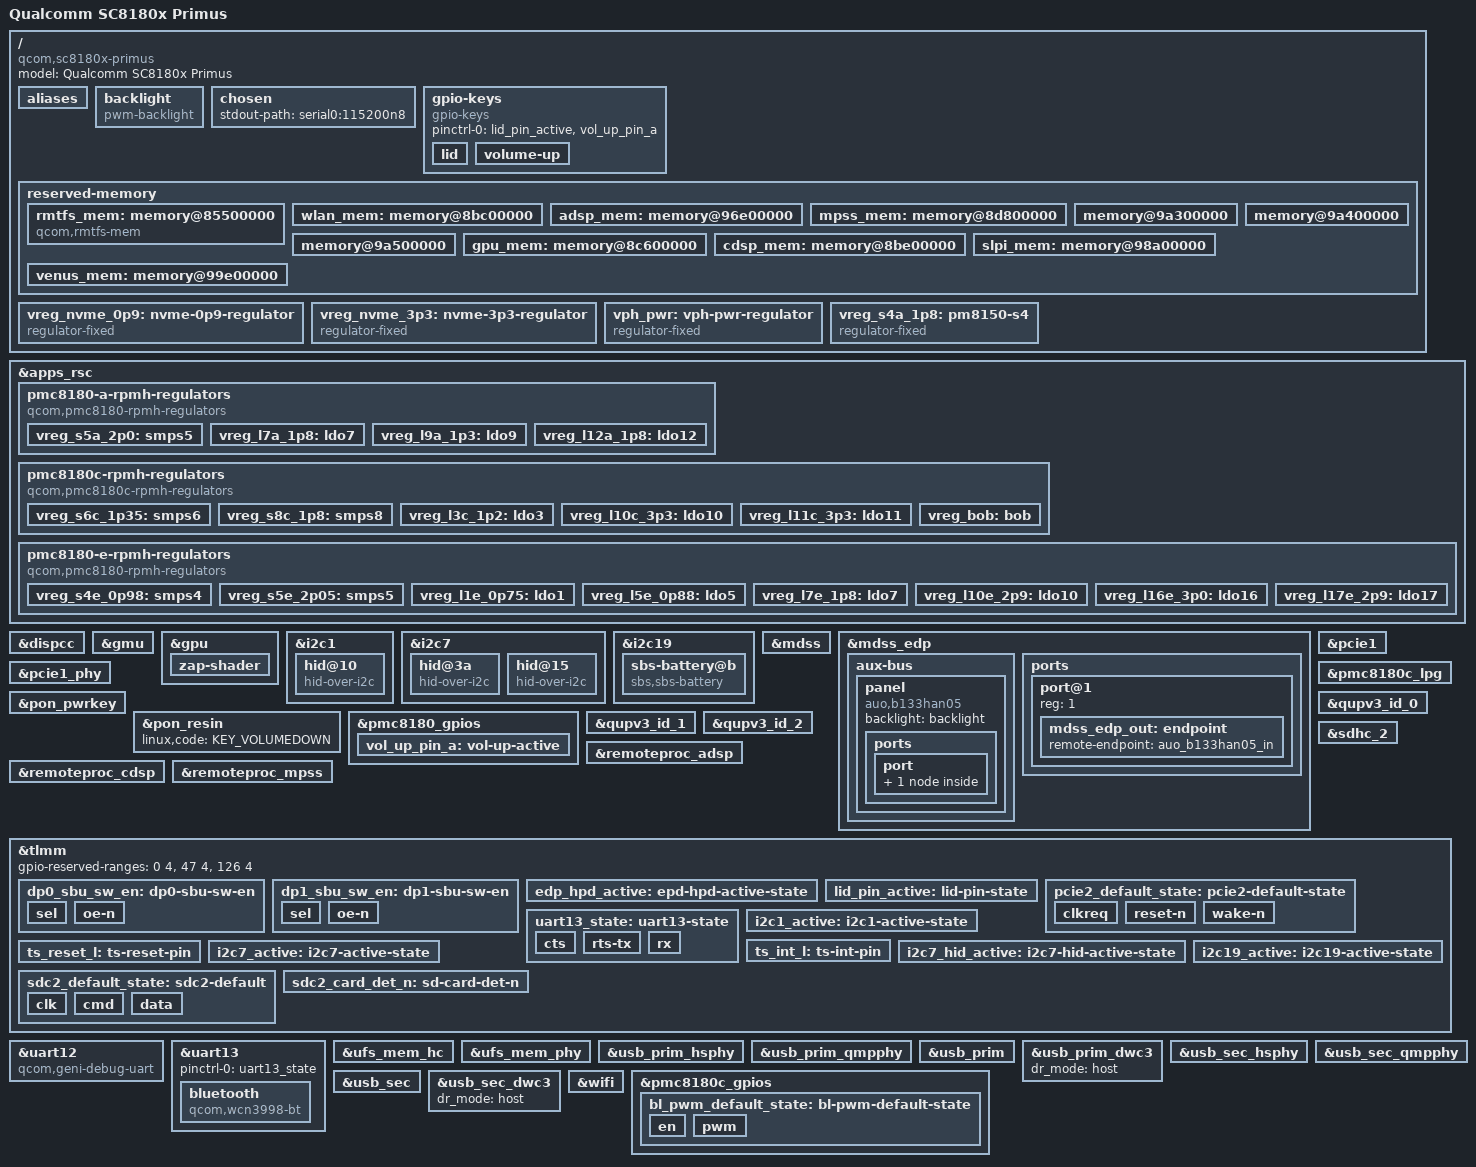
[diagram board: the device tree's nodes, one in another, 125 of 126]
// SPDX-License-Identifier: BSD-3-Clause
/*
 * Copyright (c) 2017-2019, The Linux Foundation. All rights reserved.
 * Copyright (c) 2020-2021, Linaro Limited
 */

/dts-v1/;

#include <dt-bindings/gpio/gpio.h>
#include <dt-bindings/input/gpio-keys.h>
#include <dt-bindings/input/input.h>
#include <dt-bindings/regulator/qcom,rpmh-regulator.h>
#include "sc8180x.dtsi"
#include "pmc8180.dtsi"
#include "pmc8180c.dtsi"

/ {
	model = "Qualcomm SC8180x Primus";
	compatible = "qcom,sc8180x-primus", "qcom,sc8180x";

	aliases {
		serial0 = &uart12;
		serial1 = &uart13;
		mmc0 = &sdhc_2;
	};

	backlight: backlight {
		compatible = "pwm-backlight";
		pwms = <&pmc8180c_lpg 4 1000000>;
		enable-gpios = <&pmc8180c_gpios 8 GPIO_ACTIVE_HIGH>;

		pinctrl-names = "default";
		pinctrl-0 = <&bl_pwm_default_state>;
	};

	chosen {
		stdout-path = "serial0:115200n8";
	};

	gpio-keys {
		compatible = "gpio-keys";

		pinctrl-names = "default";
		pinctrl-0 = <&lid_pin_active>, <&vol_up_pin_a>;

		lid {
			gpios = <&tlmm 121 GPIO_ACTIVE_HIGH>;
			linux,input-type = <EV_SW>;
			linux,code = <SW_LID>;
			wakeup-source;
			wakeup-event-action = <EV_ACT_DEASSERTED>;
		};

		volume-up {
			label = "volume_up";
			gpios = <&pmc8180_gpios 6 GPIO_ACTIVE_LOW>;
			linux,input-type = <1>;
			linux,code = <KEY_VOLUMEUP>;
			gpio-key,wakeup;
			debounce-interval = <15>;
			linux,can-disable;
		};
	};

	reserved-memory {
		rmtfs_mem: memory@85500000 {
			compatible = "qcom,rmtfs-mem";
			reg = <0x0 0x85500000 0x0 0x200000>;
			no-map;

			qcom,client-id = <1>;
			qcom,vmid = <15>;
		};

		wlan_mem: memory@8bc00000 {
			reg = <0x0 0x8bc00000 0x0 0x180000>;
			no-map;
		};

		adsp_mem: memory@96e00000 {
			reg = <0x0 0x96e00000 0x0 0x1c00000>;
			no-map;
		};

		mpss_mem: memory@8d800000 {
			reg = <0x0 0x8d800000 0x0 0x9600000>;
			no-map;
		};

		memory@9a300000 {
			reg = <0x0 0x9a500000 0x0 0x100000>;
			no-map;
		};

		memory@9a400000 {
			reg = <0x0 0x9a400000 0x0 0x100000>;
			no-map;
		};

		memory@9a500000 {
			reg = <0x0 0x9a500000 0x0 0x600000>;
			no-map;
		};

		gpu_mem: memory@8c600000 {
			reg = <0x0 0x8c600000 0x0 0x5000>;
			no-map;
		};

		cdsp_mem: memory@8be00000 {
			reg = <0x0 0x8be00000 0x0 0x800000>;
			no-map;
		};

		slpi_mem: memory@98a00000 {
			reg = <0x0 0x98a00000 0x0 0x1400000>;
			no-map;
		};

		venus_mem: memory@99e00000 {
			reg = <0x0 0x99e00000 0x0 0x500000>;
			no-map;
		};
	};

	vreg_nvme_0p9: nvme-0p9-regulator {
		compatible = "regulator-fixed";
		regulator-name = "vreg_nvme_0p9";

		regulator-min-microvolt = <900000>;
		regulator-max-microvolt = <900000>;

		regulator-always-on;
	};

	vreg_nvme_3p3: nvme-3p3-regulator {
		compatible = "regulator-fixed";
		regulator-name = "vreg_nvme_3p3";

		regulator-min-microvolt = <3300000>;
		regulator-max-microvolt = <3300000>;

		gpio = <&pmc8180c_gpios 11 0>;
		enable-active-high;

		regulator-always-on;
	};

	vph_pwr: vph-pwr-regulator {
		compatible = "regulator-fixed";
		regulator-name = "vph_pwr";
		regulator-min-microvolt = <3700000>;
		regulator-max-microvolt = <3700000>;
	};

	vreg_s4a_1p8: pm8150-s4 {
		compatible = "regulator-fixed";
		regulator-name = "vreg_s4a_1p8";

		regulator-min-microvolt = <1800000>;
		regulator-max-microvolt = <1800000>;

		regulator-always-on;
		regulator-boot-on;

		vin-supply = <&vph_pwr>;
	};
};

&apps_rsc {
	pmc8180-a-rpmh-regulators {
		compatible = "qcom,pmc8180-rpmh-regulators";
		qcom,pmic-id = "a";

		vdd-s5-supply = <&vph_pwr>;
		vdd-l7-l12-l14-l15-supply = <&vreg_s5a_2p0>;

		vreg_s5a_2p0: smps5 {
			regulator-min-microvolt = <2040000>;
			regulator-max-microvolt = <2100000>;
		};

		// vreg_l6a_1p2: ldo6 {
		// 	regulator-min-microvolt = <1200000>;
		// 	regulator-max-microvolt = <1200000>;
		// 	regulator-initial-mode = <RPMH_REGULATOR_MODE_HPM>;
		// };

		vreg_l7a_1p8: ldo7 {
			regulator-min-microvolt = <1800000>;
			regulator-max-microvolt = <1800000>;
			regulator-initial-mode = <RPMH_REGULATOR_MODE_HPM>;
		};


		vreg_l9a_1p3: ldo9 {
			regulator-min-microvolt = <1296000>;
			regulator-max-microvolt = <1304000>;
			regulator-initial-mode = <RPMH_REGULATOR_MODE_HPM>;
		};

		vreg_l12a_1p8: ldo12 {
			regulator-min-microvolt = <1800000>;
			regulator-max-microvolt = <1800000>;
			regulator-initial-mode = <RPMH_REGULATOR_MODE_HPM>;
		};
	};

	pmc8180c-rpmh-regulators {
		compatible = "qcom,pmc8180c-rpmh-regulators";
		qcom,pmic-id = "c";

		vdd-s6-supply = <&vph_pwr>;
		vdd-s8-supply = <&vph_pwr>;
		vdd-l2-l3-supply = <&vreg_s6c_1p35>;
		vdd-bob-supply = <&vph_pwr>;

		vreg_s6c_1p35: smps6 {
			regulator-min-microvolt = <1350000>;
			regulator-max-microvolt = <1372000>;
			regulator-initial-mode = <RPMH_REGULATOR_MODE_HPM>;
		};

		vreg_s8c_1p8: smps8 {
			regulator-min-microvolt = <1800000>;
			regulator-max-microvolt = <1800000>;
			regulator-initial-mode = <RPMH_REGULATOR_MODE_HPM>;
			regulator-always-on;
		};

		// vreg_l2c_1p2: ldo2 {
		// 	regulator-min-microvolt = <1200000>;
		// 	regulator-max-microvolt = <1200000>;
		// 	regulator-initial-mode = <RPMH_REGULATOR_MODE_HPM>;
		// };

		vreg_l3c_1p2: ldo3 {
			regulator-min-microvolt = <1200000>;
			regulator-max-microvolt = <1200000>;
			regulator-initial-mode = <RPMH_REGULATOR_MODE_HPM>;
		};

		// vreg_l6c: ldo6 {
		// 	regulator-min-microvolt = <1800000>;
		// 	regulator-max-microvolt = <2950000>;
		// 	regulator-initial-mode = <RPMH_REGULATOR_MODE_HPM>;
		// };

		// vreg_l9c_2p9: ldo9 {
		// 	regulator-min-microvolt = <2504000>;
		// 	regulator-max-microvolt = <2904000>;
		// 	regulator-initial-mode = <RPMH_REGULATOR_MODE_HPM>;
		// };

		vreg_l10c_3p3: ldo10 {
			regulator-min-microvolt = <3000000>;
			regulator-max-microvolt = <3312000>;
			regulator-initial-mode = <RPMH_REGULATOR_MODE_HPM>;
		};

		vreg_l11c_3p3: ldo11 {
			regulator-min-microvolt = <3296000>;
			regulator-max-microvolt = <3304000>;
			regulator-initial-mode = <RPMH_REGULATOR_MODE_HPM>;
		};

		vreg_bob: bob {
			regulator-min-microvolt = <3296000>;
			regulator-max-microvolt = <3350000>;
			regulator-initial-mode = <RPMH_REGULATOR_MODE_HPM>;
		};
	};

	pmc8180-e-rpmh-regulators {
		compatible = "qcom,pmc8180-rpmh-regulators";
		qcom,pmic-id = "e";

		vdd-s4-supply = <&vph_pwr>;
		vdd-s5-supply = <&vph_pwr>;
		vdd-l2-l10-supply = <&vreg_bob>;
		vdd-l3-l4-l5-l18-supply = <&vreg_s4e_0p98>;
		vdd-l7-l12-l14-l15-supply = <&vreg_s5e_2p05>;
		vdd-l13-l16-l17-supply = <&vreg_bob>;

		vreg_s4e_0p98: smps4 {
			regulator-min-microvolt = <992000>;
			regulator-max-microvolt = <992000>;
			regulator-initial-mode = <RPMH_REGULATOR_MODE_HPM>;
		};

		vreg_s5e_2p05: smps5 {
			regulator-min-microvolt = <2040000>;
			regulator-max-microvolt = <2040000>;
			regulator-initial-mode = <RPMH_REGULATOR_MODE_HPM>;
		};

		vreg_l1e_0p75: ldo1 {
			regulator-min-microvolt = <752000>;
			regulator-max-microvolt = <752000>;
			regulator-initial-mode = <RPMH_REGULATOR_MODE_HPM>;
		};

		vreg_l5e_0p88: ldo5 {
			regulator-min-microvolt = <880000>;
			regulator-max-microvolt = <880000>;
			regulator-initial-mode = <RPMH_REGULATOR_MODE_HPM>;
		};

		vreg_l7e_1p8: ldo7 {
			regulator-min-microvolt = <1800000>;
			regulator-max-microvolt = <1800000>;
			regulator-initial-mode = <RPMH_REGULATOR_MODE_HPM>;
		};

		// vreg_l9e_0p88: ldo9 {
		// 	regulator-min-microvolt = <880000>;
		// 	regulator-max-microvolt = <880000>;
		// 	regulator-initial-mode = <RPMH_REGULATOR_MODE_HPM>;
		// };

		vreg_l10e_2p9: ldo10 {
			regulator-min-microvolt = <2904000>;
			regulator-max-microvolt = <2904000>;
			regulator-initial-mode = <RPMH_REGULATOR_MODE_HPM>;
		};

		// vreg_l12e_1p8: ldo12 {
		// 	regulator-min-microvolt = <1800000>;
		// 	regulator-max-microvolt = <1800000>;
		// 	regulator-initial-mode = <RPMH_REGULATOR_MODE_HPM>;
		// };

		// vreg_l14e_1p8: ldo14 {
		// 	regulator-min-microvolt = <1800000>;
		// 	regulator-max-microvolt = <1800000>;
		// 	regulator-initial-mode = <RPMH_REGULATOR_MODE_HPM>;
		// };

		// vreg_l15e_1p8: ldo15 {
		// 	regulator-min-microvolt = <1800000>;
		// 	regulator-max-microvolt = <1800000>;
		// 	regulator-initial-mode = <RPMH_REGULATOR_MODE_HPM>;
		// };

		vreg_l16e_3p0: ldo16 {
			regulator-min-microvolt = <3072000>;
			regulator-max-microvolt = <3072000>;
			regulator-initial-mode = <RPMH_REGULATOR_MODE_HPM>;
		};

		vreg_l17e_2p9: ldo17 {
			regulator-min-microvolt = <2960000>;
			regulator-max-microvolt = <2960000>;
			regulator-initial-mode = <RPMH_REGULATOR_MODE_HPM>;
		};
	};
};

&dispcc {
	status = "okay";
};

&gmu {
	status = "okay";
};

&gpu {
	status = "okay";

	zap-shader {
		memory-region = <&gpu_mem>;
		firmware-name = "qcom/sc8180x/qcdxkmsuc8180.mbn";
	};
};

&i2c1 {
	status = "okay";
	clock-frequency = <100000>;

	pinctrl-names = "default";
	pinctrl-0 = <&i2c1_active>;

	hid@10 {
		compatible = "hid-over-i2c";
		reg = <0x10>;
		pinctrl-names = "default";
		pinctrl-0 = <&ts_int_l>, <&ts_reset_l>;

		interrupt-parent = <&tlmm>;
		interrupts = <122 IRQ_TYPE_LEVEL_LOW>;
		// interrupts-extended = <&tlmm 122 IRQ_TYPE_LEVEL_LOW>;

		post-power-on-delay-ms = <20>;
		hid-descr-addr = <0x0001>;
	};
};

&i2c7 {
	status = "okay";
	clock-frequency = <400000>;

	pinctrl-names = "default";
	pinctrl-0 = <&i2c7_active>, <&i2c7_hid_active>;

	hid@3a {
		compatible = "hid-over-i2c";
		reg = <0x3a>;
		hid-descr-addr = <0x1>;

		interrupt-parent = <&tlmm>;
		interrupts = <37 IRQ_TYPE_LEVEL_LOW>;
	};

	hid@15 {
		compatible = "hid-over-i2c";
		reg = <0x15>;
		hid-descr-addr = <0x1>;

		interrupt-parent = <&tlmm>;
		interrupts = <24 IRQ_TYPE_LEVEL_LOW>;
	};
};

&i2c19 {
	status = "okay";
	clock-frequency = <100000>;

	pinctrl-names = "default";
	pinctrl-0 = <&i2c19_active>;

	sbs-battery@b {
		compatible = "sbs,sbs-battery";
		reg = <0xb>;
		sbs,i2c-retry-count = <2>;
		sbs,poll-retry-count = <10>;
	};
};

&mdss {
	status = "okay";
};

// &mdss_dp0 {
// 	status = "okay";

// 	data-lanes = <0 1 2 3>;

// 	pinctrl-names = "default";
// 	pinctrl-0 = <&dp0_sbu_sw_en>;

// 	mode-switch;
// 	svid = /bits/ 16 <0xff01>;
// 	ports {
// 		port@2 {
// 			reg = <2>;
// 			dp0_mode: endpoint {
// 				remote-endpoint = <&ucsi_port_0_dp>;
// 			};
// 		};
// 	};
// };

// &mdss_dp1 {
// 	status = "okay";

// 	data-lanes = <0 1 2 3>;

// 	pinctrl-names = "default";
// 	pinctrl-0 = <&dp1_sbu_sw_en>;

// 	mode-switch;
// 	svid = /bits/ 16 <0xff01>;
// 	ports {
// 		port@2 {
// 			reg = <2>;
// 			dp1_mode: endpoint {
// 				remote-endpoint = <&ucsi_port_1_dp>;
// 			};
// 		};
// 	};
// };

&mdss_edp {
	status = "okay";

	data-lanes = <0 1 2 3>;

	pinctrl-names = "default";
	pinctrl-0 = <&edp_hpd_active>;

	aux-bus {
		panel {
			compatible = "auo,b133han05";
			//no-hpd;

			backlight = <&backlight>;

			ports {
				port {
					auo_b133han05_in: endpoint {
						remote-endpoint = <&mdss_edp_out>;
					};
				};
			};
		};
	};

	ports {
		port@1 {
			reg = <1>;
			mdss_edp_out: endpoint {
				remote-endpoint = <&auo_b133han05_in>;
			};
		};
	};
};

&pcie1 {
	status = "okay";
	perst-gpio = <&tlmm 175 GPIO_ACTIVE_LOW>;
	wake-gpio = <&tlmm 177 GPIO_ACTIVE_HIGH>;
	pinctrl-names = "default";
	pinctrl-0 = <&pcie2_default_state>;
};

&pcie1_phy {
	status = "okay";
	vdda-phy-supply = <&vreg_l5e_0p88>;
	vdda-pll-supply = <&vreg_l3c_1p2>;
};

&pmc8180c_lpg {
	status = "okay";
};

&pon_pwrkey {
	status = "okay";
};

&pon_resin {
	status = "okay";

	linux,code = <KEY_VOLUMEDOWN>;
};

&pmc8180_gpios {
	vol_up_pin_a: vol-up-active {
		pins = "gpio6";
		function = "normal";
		bias-pull-up;
		input-enable;
		qcom,drive-strength = <3>;
	};
};

&qupv3_id_0 {
	status = "okay";
};

&qupv3_id_1 {
	status = "okay";
};

&qupv3_id_2 {
	status = "okay";
};

&remoteproc_adsp {
	status = "okay";
	memory-region = <&adsp_mem>;
	firmware-name = "qcom/sc8180x/qcadsp8180.mbn";
};

&remoteproc_cdsp {
	status = "okay";
	memory-region = <&cdsp_mem>;
	firmware-name = "qcom/sc8180x/qccdsp8180.mbn";
};

&remoteproc_mpss {
	status = "okay";
	memory-region = <&mpss_mem>;
	firmware-name = "qcom/sc8180x/qcmpss8180.mbn";
};

&sdhc_2 {
	status = "okay";

	pinctrl-names = "default";
	pinctrl-0 = < &sdc2_default_state &sdc2_card_det_n>;

	vmmc-supply = <&vreg_l17e_2p9>;
	vqmmc-supply = <&vreg_l17e_2p9>;

	cd-gpios = <&tlmm 96 GPIO_ACTIVE_LOW>;

	no-1-8-v;
	cd-inverted;
};

&tlmm {
	gpio-reserved-ranges = <0 4>, <47 4>, <126 4>;

	dp0_sbu_sw_en: dp0-sbu-sw-en {
		sel {
			pins = "gpio100";
			function = "gpio";
			output-low;
		};

		oe-n {
			pins = "gpio152";
			function = "gpio";
			output-low;
		};
	};

	dp1_sbu_sw_en: dp1-sbu-sw-en {
		sel {
			pins = "gpio187";
			function = "gpio";
			output-low;
		};

		oe-n {
			pins = "gpio188";
			function = "gpio";
			output-low;
		};
	};

	edp_hpd_active: epd-hpd-active-state {
		pins = "gpio10";
		function = "edp_hot";
	};

	lid_pin_active: lid-pin-state {
		pins = "gpio121";
		function = "gpio";

		input-enable;
		bias-pull-down;
	};

	pcie2_default_state: pcie2-default-state {
		clkreq {
			pins = "gpio176";
			function = "pci_e2";
			bias-pull-up;
		};

		reset-n {
			pins = "gpio175";
			function = "gpio";

			drive-strength = <2>;
			output-low;
			bias-pull-down;
		};

		wake-n {
			pins = "gpio177";
			function = "gpio";

			drive-strength = <2>;
			bias-pull-up;
		};
	};

	uart13_state: uart13-state {
		cts {
			pins = "gpio43";
			function = "qup13";
			bias-pull-down;
		};

		rts-tx {
			pins = "gpio44", "gpio45";
			function = "qup13";
			drive-strength = <2>;
			bias-disable;
		};

		rx {
			pins = "gpio46";
			function = "qup13";
			bias-pull-up;
		};
	};

	i2c1_active: i2c1-active-state {
		pins = "gpio114", "gpio115";
		function = "qup1";

		bias-pull-up = <1>;
		drive-strength = <2>;
	};

	ts_int_l: ts-int-pin {
		pins = "gpio122";
		function = "gpio";

		input-enable;
		bias-pull-up;
		drive-strength = <2>;
	};

	ts_reset_l: ts-reset-pin {
		pins = "gpio54";
		function = "gpio";

		output-high;
		bias-pull-up;
		drive-strength = <2>;
	};

	i2c7_active: i2c7-active-state {
		pins = "gpio98", "gpio99";
		function = "qup7";

		bias-pull-up;
		drive-strength = <2>;
	};

	i2c7_hid_active: i2c7-hid-active-state {
		pins = "gpio37", "gpio24";
		function = "gpio";

		input-enable;
		bias-pull-up;
		drive-strength = <2>;
	};

	i2c19_active: i2c19-active-state {
		pins = "gpio180", "gpio181";
		function = "qup19";

		bias-pull-up;
		drive-strength = <2>;
	};

	sdc2_default_state: sdc2-default {
		clk {
			pins = "sdc2_clk";
			bias-disable;
		};

		cmd {
			pins = "sdc2_cmd";
			bias-pull-up;
		};

		data {
			pins = "sdc2_data";
			bias-pull-up;
		};
	};

	sdc2_card_det_n: sd-card-det-n {
		pins = "gpio96";
		function = "gpio";
		bias-pull-up;
	};
};

&uart12 {
	compatible = "qcom,geni-debug-uart";
	status = "okay";
};

&uart13 {
	status = "okay";

	pinctrl-names = "default";
	pinctrl-0 = <&uart13_state>;

	bluetooth {
		compatible = "qcom,wcn3998-bt";

		vddio-supply = <&vreg_s4a_1p8>;
		vddxo-supply = <&vreg_l7a_1p8>;
		vddrf-supply = <&vreg_l9a_1p3>;
		vddch0-supply = <&vreg_l11c_3p3>;
		max-speed = <3200000>;
	};
};

&ufs_mem_hc {
	status = "okay";

	reset-gpios = <&tlmm 190 GPIO_ACTIVE_LOW>;

	vcc-supply = <&vreg_l10e_2p9>;
	vcc-max-microamp = <155000>;

	vccq2-supply = <&vreg_l7e_1p8>;
	vccq2-max-microamp = <425000>;
};

&ufs_mem_phy {
	status = "okay";

	vdda-phy-supply = <&vreg_l5e_0p88>;
	vdda-pll-supply = <&vreg_l3c_1p2>;
};

&usb_prim_hsphy {
	status = "okay";
	vdda-pll-supply = <&vreg_l5e_0p88>;
	vdda18-supply = <&vreg_l12a_1p8>;
	vdda33-supply = <&vreg_l16e_3p0>;
};

&usb_prim_qmpphy {
	status = "okay";
	vdda-phy-supply = <&vreg_l3c_1p2>;
	vdda-pll-supply = <&vreg_l5e_0p88>;
};

&usb_prim {
	status = "okay";
};

&usb_prim_dwc3 {
	dr_mode = "host";
};

&usb_sec_hsphy {
	status = "okay";
	vdda-pll-supply = <&vreg_l5e_0p88>;
	vdda18-supply = <&vreg_l12a_1p8>;
	vdda33-supply = <&vreg_l16e_3p0>;
};

&usb_sec_qmpphy {
	status = "okay";
	vdda-phy-supply = <&vreg_l3c_1p2>;
	vdda-pll-supply = <&vreg_l5e_0p88>;
};

&usb_sec {
	status = "okay";
};

&usb_sec_dwc3 {
	dr_mode = "host";
};

&wifi {
	status = "okay";

	memory-region = <&wlan_mem>;

	vdd-0.8-cx-mx-supply = <&vreg_l1e_0p75>;
	vdd-1.8-xo-supply = <&vreg_l7a_1p8>;
	vdd-1.3-rfa-supply = <&vreg_l9a_1p3>;
	vdd-3.3-ch0-supply = <&vreg_l11c_3p3>;
	vdd-3.3-ch1-supply = <&vreg_l10c_3p3>;
};

/* PINCTRL */

&pmc8180c_gpios {
	bl_pwm_default_state: bl-pwm-default-state {
		en {
			pins = "gpio8";
			function = "normal";
		};

		pwm {
			pins = "gpio10";
			function = "func1";
		};
	};
};
